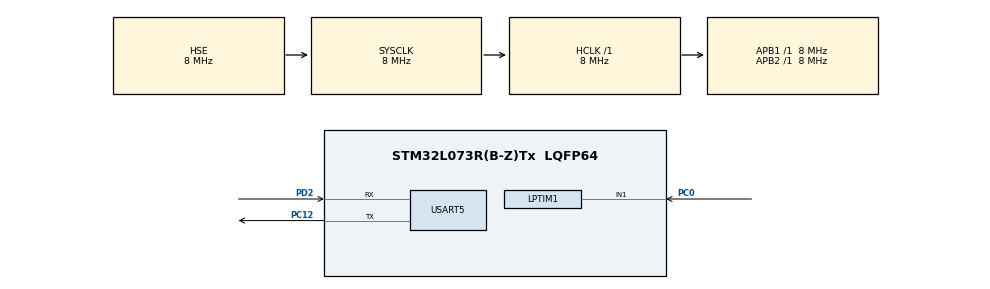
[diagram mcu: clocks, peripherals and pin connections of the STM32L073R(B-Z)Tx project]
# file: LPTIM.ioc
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Mcu.Family=STM32L0
Mcu.Name=STM32L073R(B-Z)Tx
Mcu.Package=LQFP64
NVIC.RTC_IRQn=true\:0\:0\:false\:false\:true\:true\:true
NVIC.TIM7_IRQn=true\:0\:0\:false\:false\:true\:false\:true
NVIC.TimeBase=TIM7_IRQn
NVIC.TimeBaseIP=TIM7
NVIC.USART4_5_IRQn=true\:0\:0\:false\:false\:true\:true\:true
PA13.Mode=Serial_Wire
PA13.Signal=SYS_SWDIO
PA14.Mode=Serial_Wire
PA14.Signal=SYS_SWCLK
PC0.Mode=Counts_external_clock_with_synchro_01_occur1
PC0.Signal=LPTIM1_IN1
PC12.Mode=Asynchronous
PC12.Signal=USART5_TX
PC14-OSC32_IN.Mode=LSE-External-Oscillator
PC14-OSC32_IN.Signal=RCC_OSC32_IN
PC15-OSC32_OUT.Mode=LSE-External-Oscillator
PC15-OSC32_OUT.Signal=RCC_OSC32_OUT
PD2.Mode=Asynchronous
PD2.Signal=USART5_RX
PH0-OSC_IN.Mode=HSE-External-Oscillator
PH0-OSC_IN.Signal=RCC_OSC_IN
PH1-OSC_OUT.Mode=HSE-External-Oscillator
PH1-OSC_OUT.Signal=RCC_OSC_OUT
ProjectManager.HeapSize=0x200
ProjectManager.StackSize=0x400
ProjectManager.TargetToolchain=MDK-ARM V5
RCC.AHBFreq_Value=8000000
RCC.APB1Freq_Value=8000000
RCC.APB1TimFreq_Value=8000000
RCC.APB2Freq_Value=8000000
RCC.APB2TimFreq_Value=8000000
RCC.HCLKFreq_Value=8000000
RCC.HSE_VALUE=8000000
RCC.HSI16_VALUE=16000000
RCC.HSI48_VALUE=48000000
RCC.HSI_VALUE=16000000
RCC.LptimClockSelection=RCC_LPTIM1CLKSOURCE_LSE
RCC.Lpuart1ClockSelection=RCC_LPUART1CLKSOURCE_LSE
RCC.MSI_VALUE=2097000
RCC.RTCClockSelectionVirtual=RCC_RTCCLKSOURCE_LSE
RCC.SYSCLKFreq_VALUE=8000000
RCC.SYSCLKSource=RCC_SYSCLKSOURCE_HSE
RCC.VCOOutputFreq_Value=48000000
RTC.Date=1
RTC.Format=RTC_FORMAT_BIN
RTC.HourFormat=RTC_HOURFORMAT_12
RTC.Hours=12
RTC.Minutes=30
RTC.Month=RTC_MONTH_MAY
RTC.Seconds=30
RTC.WakeUpClock-WakeUp=RTC_WAKEUPCLOCK_CK_SPRE_16BITS
RTC.WakeUpCounter-WakeUp=9
RTC.WeekDay=RTC_WEEKDAY_FRIDAY
RTC.Year=20
USART5.VirtualMode-Asynchronous=VM_ASYNC
VP_RTC_VS_RTC_Activate.Mode=RTC_Enabled
VP_RTC_VS_RTC_Calendar.Mode=RTC_Calendar
VP_RTC_VS_RTC_WakeUp_intern.Mode=WakeUp
VP_SYS_VS_tim7.Mode=TIM7
board=custom

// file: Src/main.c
/* USER CODE BEGIN Header */
/**
  ******************************************************************************
  * @file           : main.c
  * @brief          : Main program body
  ******************************************************************************
  * @attention
  *
  * <h2><center>&copy; Copyright (c) 2020 STMicroelectronics.
  * All rights reserved.</center></h2>
  *
  * This software component is licensed by ST under BSD 3-Clause license,
  * the "License"; You may not use this file except in compliance with the
  * License. You may obtain a copy of the License at:
  *                        opensource.org/licenses/BSD-3-Clause
  *
  ******************************************************************************
  */
/* USER CODE END Header */

#include "main.h"
#include "lptim.h"
#include "rtc.h"
#include "usart.h"
#include "gpio.h"

void SystemClock_Config(void);

/* USER CODE BEGIN 0 */

void Enter_StopMode_Time(uint32_t time)
{
    /* Enable Ultra low power mode */
    HAL_PWREx_EnableUltraLowPower();
    HAL_PWREx_EnableFastWakeUp();
    HAL_RTCEx_DeactivateWakeUpTimer(&hrtc);
    if(time < 10)  time = 10;
    if(time >= 3600) time = 3600;
//	HAL_RTCEx_SetWakeUpTimer_IT(&hrtc, 60*2048, RTC_WAKEUPCLOCK_RTCCLK_DIV16);
    HAL_RTCEx_SetWakeUpTimer_IT(&hrtc, (time-1), RTC_WAKEUPCLOCK_CK_SPRE_16BITS);

//	HAL_PWR_EnterSTOPMode(PWR_LOWPOWERREGULATOR_ON, PWR_STOPENTRY_WFI);
}
/* USER CODE END 0 */

int main(void)
{

  /* MCU Configuration--------------------------------------------------------*/

  /* Reset of all peripherals, Initializes the Flash interface and the Systick. */
  HAL_Init();

  /* Configure the system clock */
  SystemClock_Config();

  /* Initialize all configured peripherals */
  MX_GPIO_Init();
  MX_LPTIM1_Init();
  MX_RTC_Init();
  MX_USART5_UART_Init();

  /* Infinite loop */
  /* USER CODE BEGIN WHILE */
//  HAL_LPTIM_Counter_Start(&hlptim1,1000);
//  Enter_StopMode_Time(10);
  while (1)
  {
    /* USER CODE END WHILE */

  }
}

void SystemClock_Config(void)
{
  RCC_OscInitTypeDef RCC_OscInitStruct = {0};
  RCC_ClkInitTypeDef RCC_ClkInitStruct = {0};
  RCC_PeriphCLKInitTypeDef PeriphClkInit = {0};

  /** Configure the main internal regulator output voltage
  */
  __HAL_PWR_VOLTAGESCALING_CONFIG(PWR_REGULATOR_VOLTAGE_SCALE1);
  /** Configure LSE Drive Capability
  */
  HAL_PWR_EnableBkUpAccess();
  __HAL_RCC_LSEDRIVE_CONFIG(RCC_LSEDRIVE_LOW);
  /** Initializes the CPU, AHB and APB busses clocks
  */
  RCC_OscInitStruct.OscillatorType = RCC_OSCILLATORTYPE_HSE|RCC_OSCILLATORTYPE_LSE;
  RCC_OscInitStruct.HSEState = RCC_HSE_ON;
  RCC_OscInitStruct.LSEState = RCC_LSE_ON;
  RCC_OscInitStruct.PLL.PLLState = RCC_PLL_NONE;
  if (HAL_RCC_OscConfig(&RCC_OscInitStruct) != HAL_OK)
  {
    Error_Handler();
  }
  /** Initializes the CPU, AHB and APB busses clocks
  */
  RCC_ClkInitStruct.ClockType = RCC_CLOCKTYPE_HCLK|RCC_CLOCKTYPE_SYSCLK
                              |RCC_CLOCKTYPE_PCLK1|RCC_CLOCKTYPE_PCLK2;
  RCC_ClkInitStruct.SYSCLKSource = RCC_SYSCLKSOURCE_HSE;
  RCC_ClkInitStruct.AHBCLKDivider = RCC_SYSCLK_DIV1;
  RCC_ClkInitStruct.APB1CLKDivider = RCC_HCLK_DIV1;
  RCC_ClkInitStruct.APB2CLKDivider = RCC_HCLK_DIV1;

  if (HAL_RCC_ClockConfig(&RCC_ClkInitStruct, FLASH_LATENCY_0) != HAL_OK)
  {
    Error_Handler();
  }
  PeriphClkInit.PeriphClockSelection = RCC_PERIPHCLK_RTC|RCC_PERIPHCLK_LPTIM1;
  PeriphClkInit.RTCClockSelection = RCC_RTCCLKSOURCE_LSE;
  PeriphClkInit.LptimClockSelection = RCC_LPTIM1CLKSOURCE_LSE;

  if (HAL_RCCEx_PeriphCLKConfig(&PeriphClkInit) != HAL_OK)
  {
    Error_Handler();
  }
}

/* USER CODE BEGIN 4 */
///重定向c库函数printf到串口DEBUG_USART，重定向后可使用printf函数
int fputc(int ch, FILE *f)
{
    /* 发送一个字节数据到串口DEBUG_USART */
    HAL_UART_Transmit(&huart5, (uint8_t *)&ch, 1, 1000);

    return (ch);
}

///重定向c库函数scanf到串口DEBUG_USART，重写向后可使用scanf、getchar等函数
int fgetc(FILE *f)
{
    int ch;
    HAL_UART_Receive(&huart5, (uint8_t *)&ch, 1, 1000);
    return (ch);
}
/* USER CODE END 4 */

 /**
  * @brief  Period elapsed callback in non blocking mode
  * @note   This function is called  when TIM7 interrupt took place, inside
  * HAL_TIM_IRQHandler(). It makes a direct call to HAL_IncTick() to increment
  * a global variable "uwTick" used as application time base.
  * @param  htim : TIM handle
  * @retval None
  */
void HAL_TIM_PeriodElapsedCallback(TIM_HandleTypeDef *htim)
{
  if (htim->Instance == TIM7) {
    HAL_IncTick();
  }
}

void Error_Handler(void)
{
}

/************************ (C) COPYRIGHT STMicroelectronics *****END OF FILE****/
